# iND83216 register map
Vendor: Indiemicro; Series: RealplumTiny; File version: 1.00
CPU: CM0 r0p1, selectable endian, no MPU, no FPU, 4 interrupt priority bits
Registers are 32-bit, read-write, no defined reset value unless marked. A register's access mark holds for its fields unless they carry their own. Offsets are from the block's base; [hi:lo] are bit positions.

## PMUA — Power Management Unit
Base 0x50000400; register names take the prefix PMUA_
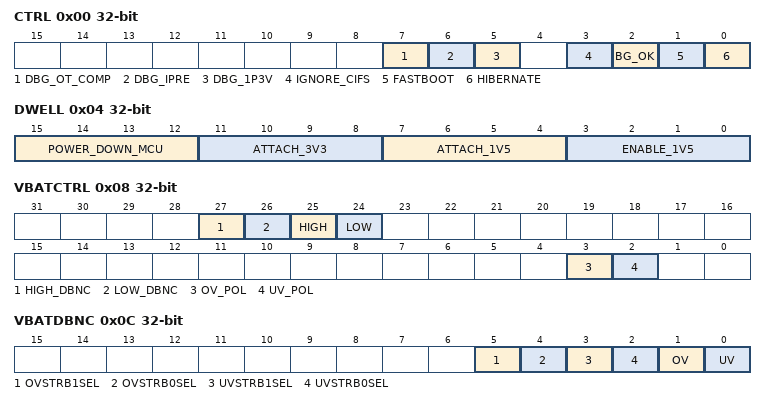
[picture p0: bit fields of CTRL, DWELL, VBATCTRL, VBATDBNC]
0x00 CTRL — Control
  [7] DBG_OT_COMP — Enable to test the comparator of over temperature function.
  [6] DBG_IPRE — EN test IBIAS_PRE 1uA current.
  [5] DBG_1P3V — LDO_1V5 output 1.35V, Set to 1V5-LDO output 1V35.
  [3] IGNORE_CIFS — Ignore QACKs. Setting a bit in this register prevents PMUA from waiting for the assertion of the corresponding 'Quiescent State Acknowlege' signal when before transitioning towards the Hibernate state.
  [2] BG_OK ro — the flag of bandgap OK. the flag of bandgap OK
  [1] FASTBOOT — Fast boot. Set to enable used of the fast clock during subsequent power-up sequences (including the portion consumed by the Clough boot sequence). The set value brings the system up with the slow clock to make the initial boot and any boot after a hard reset (e.g. after a brownout) as safe as possible.
  [0] HIBERNATE wo — Hibernate. Set to put the chip into HIBERATE mode. Before setting this bit, ensure that wake interrupt controller HOLD bit has been set (and that a corresponding Lullaby interrupt has been received).
0x04 DWELL — Dwell NOTE:The write operation of this field register takes effect by configuring 'SYSCTRLA_SFRS->TRIM_ACCESS_KEY.TRIM_ACCESS_KEY = 0x0E'
  [15:12] POWER_DOWN_MCU — Power down MCU dwell time. Defines the amount of time spent in the 'Power down MCU' state. Pausing here allows the MCU supplies to discharge (to guarantee subsequent POR)
  [11:8] ATTACH_3V3 — Attach 3.3V dwell time. Defines the amount of time spent in the 'Attach 3V3' state. State Attaches 3.3V to MCU.
  [7:4] ATTACH_1V5 — Attach 1.5V dwell time. Defines the amount of time spent in the 'Attach 1V5' state. State Attaches 1.5V to MCU.
  [3:0] ENABLE_1V5 — Enable 1.5V dwell time. Defines the amount of time spent in the 'Enable 1V5' state. Allows 3v3 and 1v5 regs to settle
0x08 VBATCTRL — VBAT Monitor Register
  [27] HIGH_DBNC ro — Battery Voltage High Status after deboucing. Battery monitor over voltage event signal coming from the debouncer of analog comparator circuit.
  [26] LOW_DBNC ro — Battery Voltage Low Status after debouncing. Battery monitor under voltage event signal coming from the debouncer of analog comparator circuit.
  [25] HIGH ro — Battery Voltage High Status. RAW battery monitor over voltage event signal coming from the analog comparator circuit.
  [24] LOW ro — Battery Voltage Low Status. RAW battery monitor under voltage event signal coming from the analog comparator circuit.
  [3] OV_POL — Battery Voltage Monitor Over Voltage Interrupt Event Polarity. Flips the over voltage event signal coming from the analog comparator circuit which feeds into the interrupt generator.0x0: Native Polarity0x1: Flip Polarity
  [2] UV_POL — Battery Voltage Monitor Under Voltage Interrupt Event Polarity. Flips the under voltage event signal coming from the analog comparator circuit which feeds into the interrupt generator.0x0: Native Polarity0x1: Flip Polarity
0x0C VBATDBNC — VBAT Debounce Register
  [5] OVSTRB1SEL — Low frequency strobing select for debouncing. Enables strobing 1 with the Low frequency clock(16K) instead of just clocking with High frequency Clock(16M). Default is set to 0 for quick acknowledgement of OV event.
  [4] OVSTRB0SEL — Low frequency strobing select for debouncing. Enables strobing 0 with the Low frequency clock(16K) instead of just clocking with High frequency Clock(16M). Default is set to 1 for debouncing of OV.
  [3] UVSTRB1SEL — Low frequency strobing select for debouncing. Enables strobing 1 with the Low frequency clock(16K) instead of just clocking with High frequency Clock(16M). Default is set to 0 for quick acknowledgement of UV event.
  [2] UVSTRB0SEL — Low frequency strobing select for debouncing. Enables strobing 0 with the Low frequency clock(16K) instead of just clocking with High frequency Clock(16M). Default is set to 1 for debouncing of UV.
  [1] OV — over voltage signal debounce enable. if set to '1, debounces the over voltage signal before going to over voltage interrupt generation else the signal bypass the debouncer
  [0] UV — under voltage signal debounce enable. if set to '1, debounces the under voltage signal before going to under voltage interrupt generation else the signal bypass the debouncer
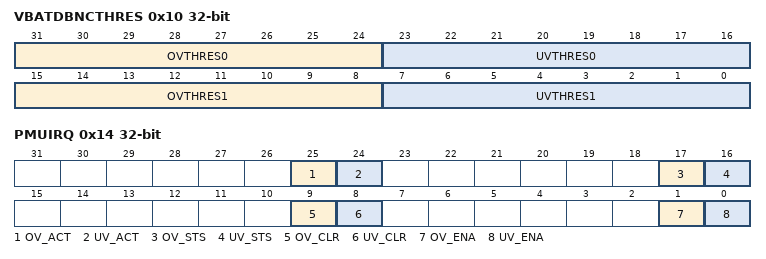
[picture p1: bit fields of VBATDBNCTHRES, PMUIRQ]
0x10 VBATDBNCTHRES — VBAT Monitor Threshold Register
  [31:24] OVTHRES0 — Over Voltage debouncing threshold for 1to0 Transition. Sets the threshold for debouncing the over voltage event going from 1 to 0. It will require the ov event to stay high for the (OVTHRES0+1) number of LF/HF clocks to transit from a 1 to 0.
  [23:16] UVTHRES0 — Under Voltage debouncing threshold for 1to0 Transition. Sets the threshold for debouncing the under voltage event going from 1 to 0. It will require the uv event to stay high for the (UVTHRES0+1) number of LF/HF clocks to transit from a 1 to 0.
  [15:8] OVTHRES1 — Over Voltage debouncing threshold for 0to1 Transition. Sets the threshold for debouncing the over voltage event going from 0 to 1. It will require the ov event to stay high for the (OVTHRES1+1) number of LF/HF clocks to transit from a 0 to 1.
  [7:0] UVTHRES1 — Under Voltage debouncing threshold for 0to1 Transition. Sets the threshold for debouncing the under voltage event going from 0 to 1. It will require the uv event to stay high for the (UVTHRES1+1) number of LF/HF clocks to transit from a 0 to 1.
0x14 PMUIRQ — Voltage Monitor interrupts
  [25] OV_ACT ro — over voltage interrupt active.
  [24] UV_ACT ro — under voltage interrupt active.
  [17] OV_STS ro — over voltage interrupt status.
  [16] UV_STS ro — under voltage interrupt status.
  [9] OV_CLR wo — over voltage interrupt clear. Autoclear: includes a synchronous reset signal which clears the register on the cycle following write.
  [8] UV_CLR wo — under voltage interrupt clear. Autoclear: includes a synchronous reset signal which clears the register on the cycle following write.
  [1] OV_ENA — over voltage interrupt enable.
  [0] UV_ENA — under voltage interrupt enable.
